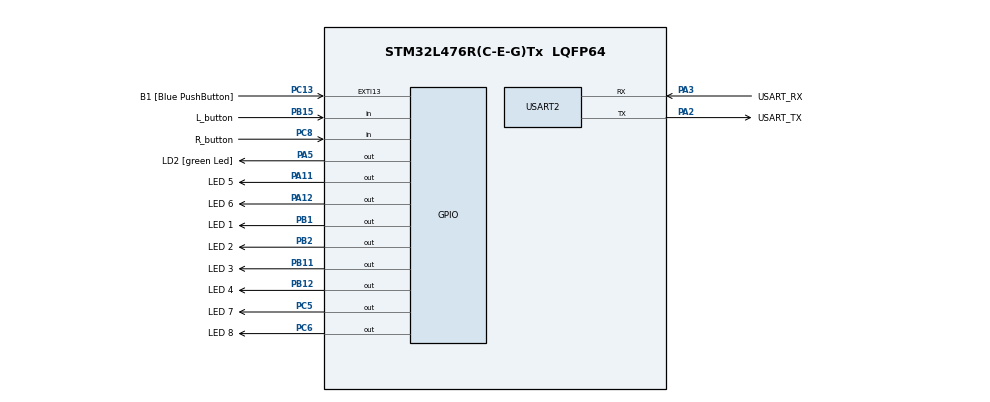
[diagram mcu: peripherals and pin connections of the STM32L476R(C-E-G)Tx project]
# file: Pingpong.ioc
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Mcu.Family=STM32L4
Mcu.Name=STM32L476R(C-E-G)Tx
Mcu.Package=LQFP64
NVIC.PriorityGroup=NVIC_PRIORITYGROUP_4
PA11.GPIO_Label=LED 5
PA11.Signal=GPIO_Output
PA12.GPIO_Label=LED 6
PA12.Signal=GPIO_Output
PA13\ (JTMS-SWDIO).GPIO_Label=TMS
PA13\ (JTMS-SWDIO).Mode=Serial_Wire
PA13\ (JTMS-SWDIO).Signal=SYS_JTMS-SWDIO
PA14\ (JTCK-SWCLK).GPIO_Label=TCK
PA14\ (JTCK-SWCLK).Mode=Serial_Wire
PA14\ (JTCK-SWCLK).Signal=SYS_JTCK-SWCLK
PA2.GPIO_Label=USART_TX
PA2.GPIO_Mode=GPIO_MODE_AF_PP
PA2.GPIO_PuPd=GPIO_NOPULL
PA2.GPIO_Speed=GPIO_SPEED_FREQ_VERY_HIGH
PA2.Mode=Asynchronous
PA2.Signal=USART2_TX
PA3.GPIO_Label=USART_RX
PA3.GPIO_Mode=GPIO_MODE_AF_PP
PA3.GPIO_PuPd=GPIO_NOPULL
PA3.GPIO_Speed=GPIO_SPEED_FREQ_VERY_HIGH
PA3.Mode=Asynchronous
PA3.Signal=USART2_RX
PA5.GPIO_Label=LD2 [green Led]
PA5.GPIO_ModeDefaultOutputPP=GPIO_MODE_OUTPUT_PP
PA5.GPIO_PuPd=GPIO_NOPULL
PA5.GPIO_Speed=GPIO_SPEED_FREQ_LOW
PA5.Signal=GPIO_Output
PB1.GPIO_Label=LED 1
PB1.Signal=GPIO_Output
PB11.GPIO_Label=LED 3
PB11.Signal=GPIO_Output
PB12.GPIO_Label=LED 4
PB12.Signal=GPIO_Output
PB15.GPIO_Label=L_button
PB15.GPIO_PuPd=GPIO_PULLUP
PB15.Signal=GPIO_Input
PB2.GPIO_Label=LED 2
PB2.Signal=GPIO_Output
PB3\ (JTDO-TRACESWO).GPIO_Label=SWO
PB3\ (JTDO-TRACESWO).Signal=SYS_JTDO-SWO
PC13.GPIO_Label=B1 [Blue PushButton]
PC13.GPIO_ModeDefaultEXTI=GPIO_MODE_IT_FALLING
PC13.GPIO_PuPd=GPIO_NOPULL
PC13.Signal=GPXTI13
PC14-OSC32_IN\ (PC14).Mode=LSE-External-Oscillator
PC14-OSC32_IN\ (PC14).Signal=RCC_OSC32_IN
PC15-OSC32_OUT\ (PC15).Mode=LSE-External-Oscillator
PC15-OSC32_OUT\ (PC15).Signal=RCC_OSC32_OUT
PC5.GPIO_Label=LED 7
PC5.Signal=GPIO_Output
PC6.GPIO_Label=LED 8
PC6.Signal=GPIO_Output
PC8.GPIO_Label=R_button
PC8.GPIO_PuPd=GPIO_PULLUP
PC8.Signal=GPIO_Input
PH0-OSC_IN\ (PH0).Signal=RCC_OSC_IN
PH1-OSC_OUT\ (PH1).Signal=RCC_OSC_OUT
ProjectManager.HeapSize=0x200
ProjectManager.StackSize=0x400
ProjectManager.TargetToolchain=STM32CubeIDE
RCC.ADCFreq_Value=64000000
RCC.AHBFreq_Value=80000000
RCC.APB1Freq_Value=80000000
RCC.APB1TimFreq_Value=80000000
RCC.APB2Freq_Value=80000000
RCC.APB2TimFreq_Value=80000000
RCC.CortexFreq_Value=80000000
RCC.HCLKFreq_Value=80000000
RCC.HSE_VALUE=8000000
RCC.HSI_VALUE=16000000
RCC.MSI_VALUE=4000000
RCC.PLLN=10
RCC.PLLSourceVirtual=RCC_PLLSOURCE_HSI
RCC.PREFETCH_ENABLE=1
RCC.SYSCLKFreq_VALUE=80000000
RCC.SYSCLKSource=RCC_SYSCLKSOURCE_PLLCLK
RCC.USBFreq_Value=64000000
RCC.VCOOutputFreq_Value=160000000
USART2.VirtualMode-Asynchronous=VM_ASYNC
board=NUCLEO-L476RG

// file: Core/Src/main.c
/* USER CODE BEGIN Header */
/**
  ******************************************************************************
  * @file           : main.c
  * @brief          : Main program body
  ******************************************************************************
  * @attention
  *
  * <h2><center>&copy; Copyright (c) 2019 STMicroelectronics.
  * All rights reserved.</center></h2>
  *
  * This software component is licensed by ST under BSD 3-Clause license,
  * the "License"; You may not use this file except in compliance with the
  * License. You may obtain a copy of the License at:
  *                        opensource.org/licenses/BSD-3-Clause
  *
  ******************************************************************************
  */
/* USER CODE END Header */

#include "main.h"

/* USER CODE BEGIN PD */
#define RUN_TEST_PROGRAM
/* USER CODE END PD */

/* USER CODE BEGIN 0 */
#ifdef RUN_TEST_PROGRAM
extern void initialise_monitor_handles(void);
#endif
/* USER CODE END 0 */

int main(void)
{
  /* USER CODE BEGIN 1 */
//#undef RUN_TEST_PROGRAM
  /* USER CODE END 1 */

  /* MCU Configuration--------------------------------------------------------*/

  /* Reset of all peripherals, Initializes the Flash interface and the Systick. */
  HAL_Init();

  /* Configure the system clock */
  SystemClock_Config();

  /* Initialize all configured peripherals */
  MX_GPIO_Init();
  MX_USART2_UART_Init();

  /* Infinite loop */
  while (1)
  {
	#ifdef RUN_TEST_PROGRAM
	  Test_program();
	#else
	  Pingpong();
	#endif
  }
}

void Error_Handler(void)
{
}

/************************ (C) COPYRIGHT STMicroelectronics *****END OF FILE****/
